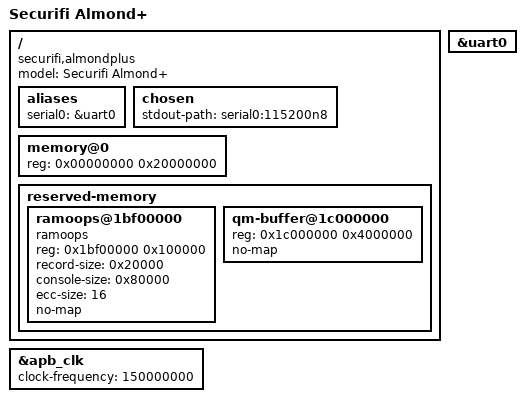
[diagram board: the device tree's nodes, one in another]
// SPDX-License-Identifier: (GPL-2.0-or-later OR MIT)
/*
 * Device Tree Source for the Securifi Almond+ router
 */

/dts-v1/;

#include "cs7542.dtsi"

/ {
	model = "Securifi Almond+";
	compatible = "securifi,almondplus", "cortina,cs7542";

	aliases {
		serial0 = &uart0;
	};

	chosen {
		stdout-path = "serial0:115200n8";
	};

	memory@0 {
		device_type = "memory";
		reg = <0x00000000 0x20000000>;
	};

	reserved-memory {
		ranges;
		#address-cells = <1>;
		#size-cells = <1>;

		ramoops@1bf00000 {
			compatible = "ramoops";
			reg = <0x1bf00000 0x100000>;
			record-size = <0x20000>;
			console-size = <0x80000>;
			ecc-size = <16>;
			no-map;
		};

		/* Reserved for the packet engine queue manager */
		qm-buffer@1c000000 {
			reg = <0x1c000000 0x4000000>;
			no-map;
		};
	};
};

&apb_clk {
	clock-frequency = <150000000>;
};

&uart0 {
	status = "okay";
};
